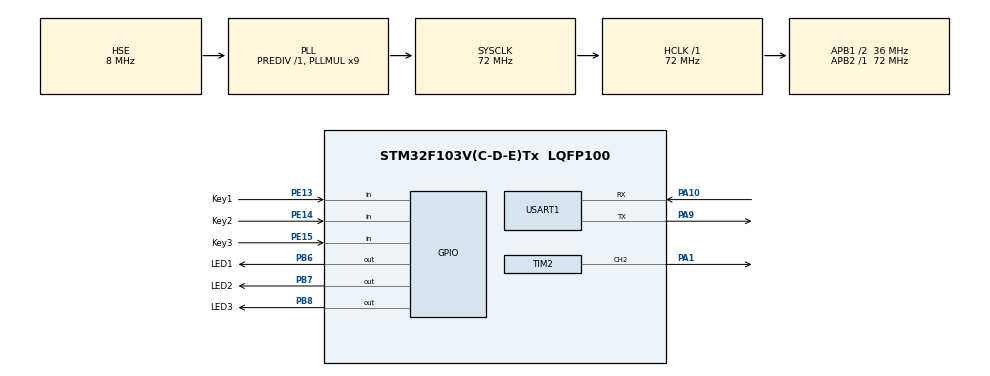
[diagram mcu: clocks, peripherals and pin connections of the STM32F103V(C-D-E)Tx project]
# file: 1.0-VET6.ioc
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Mcu.Family=STM32F1
Mcu.Name=STM32F103V(C-D-E)Tx
Mcu.Package=LQFP100
NVIC.PriorityGroup=NVIC_PRIORITYGROUP_4
NVIC.TIM2_IRQn=true\:2\:0\:true\:false\:true\:true\:true\:true
NVIC.TIM7_IRQn=true\:15\:0\:false\:false\:true\:false\:true\:true
NVIC.TimeBase=TIM7_IRQn
NVIC.TimeBaseIP=TIM7
OSC_IN.Mode=HSE-External-Oscillator
OSC_IN.Signal=RCC_OSC_IN
OSC_OUT.Mode=HSE-External-Oscillator
OSC_OUT.Signal=RCC_OSC_OUT
PA1.Signal=S_TIM2_CH2
PA10.Mode=Asynchronous
PA10.Signal=USART1_RX
PA13.Mode=Serial_Wire
PA13.Signal=SYS_JTMS-SWDIO
PA14.Mode=Serial_Wire
PA14.Signal=SYS_JTCK-SWCLK
PA9.Mode=Asynchronous
PA9.Signal=USART1_TX
PB6.GPIO_Label=LED1
PB6.GPIO_Speed=GPIO_SPEED_FREQ_HIGH
PB6.Signal=GPIO_Output
PB7.GPIO_Label=LED2
PB7.GPIO_Speed=GPIO_SPEED_FREQ_HIGH
PB7.Signal=GPIO_Output
PB8.GPIO_Label=LED3
PB8.GPIO_Speed=GPIO_SPEED_FREQ_HIGH
PB8.Signal=GPIO_Output
PC14-OSC32_IN.Mode=LSE-External-Oscillator
PC14-OSC32_IN.Signal=RCC_OSC32_IN
PC15-OSC32_OUT.Mode=LSE-External-Oscillator
PC15-OSC32_OUT.Signal=RCC_OSC32_OUT
PE13.GPIO_Label=Key1
PE13.Signal=GPIO_Input
PE14.GPIO_Label=Key2
PE14.Signal=GPIO_Input
PE15.GPIO_Label=Key3
PE15.Signal=GPIO_Input
ProjectManager.HeapSize=0x200
ProjectManager.StackSize=0x400
ProjectManager.TargetToolchain=MDK-ARM V5.32
RCC.AHBFreq_Value=72000000
RCC.APB1CLKDivider=RCC_HCLK_DIV2
RCC.APB1Freq_Value=36000000
RCC.APB1TimFreq_Value=72000000
RCC.APB2Freq_Value=72000000
RCC.APB2TimFreq_Value=72000000
RCC.HCLKFreq_Value=72000000
RCC.PLLMUL=RCC_PLL_MUL9
RCC.PLLSourceVirtual=RCC_PLLSOURCE_HSE
RCC.SYSCLKFreq_VALUE=72000000
RCC.SYSCLKSource=RCC_SYSCLKSOURCE_PLLCLK
RCC.USBFreq_Value=72000000
SH.S_TIM2_CH2.0=TIM2_CH2,PWM Generation2 CH2
TIM2.Channel-Output\ Compare1\ No\ Output=TIM_CHANNEL_1
TIM2.Channel-PWM\ Generation2\ CH2=TIM_CHANNEL_2
TIM2.Period=1000-1
TIM2.Prescaler=72-1
TIM2.Pulse-Output\ Compare1\ No\ Output=550
TIM2.Pulse-PWM\ Generation2\ CH2=500
USART1.VirtualMode=VM_ASYNC
VP_SYS_VS_tim7.Mode=TIM7
VP_TIM2_VS_ClockSourceINT.Mode=Internal
VP_TIM2_VS_no_output1.Mode=Output Compare1 No Output
board=custom

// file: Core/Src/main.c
/* USER CODE BEGIN Header */
/**
  ******************************************************************************
  * @file           : main.c
  * @brief          : Main program body
  ******************************************************************************
  * @attention
  *
  * Copyright (c) 2026 STMicroelectronics.
  * All rights reserved.
  *
  * This software is licensed under terms that can be found in the LICENSE file
  * in the root directory of this software component.
  * If no LICENSE file comes with this software, it is provided AS-IS.
  *
  ******************************************************************************
  */
/* USER CODE END Header */
#include "main.h"
#include "tim.h"
#include "usart.h"
#include "gpio.h"

void SystemClock_Config(void);

int main(void)
{

  /* USER CODE BEGIN 1 */
	uint16_t i=0;
  /* USER CODE END 1 */

  /* MCU Configuration--------------------------------------------------------*/

  /* Reset of all peripherals, Initializes the Flash interface and the Systick. */
  HAL_Init();

  /* Configure the system clock */
  SystemClock_Config();

  /* Initialize all configured peripherals */
  MX_GPIO_Init();
  MX_USART1_UART_Init();
  MX_TIM2_Init();
  /* USER CODE BEGIN 2 */
	HAL_TIM_OC_Start_IT(&htim2, TIM_CHANNEL_1);
	HAL_TIM_PWM_Start(&htim2, TIM_CHANNEL_2);

  /* USER CODE END 2 */

  /* Infinite loop */
  while (1)
  {

  }
}

void SystemClock_Config(void)
{
  RCC_OscInitTypeDef RCC_OscInitStruct = {0};
  RCC_ClkInitTypeDef RCC_ClkInitStruct = {0};

  /** Initializes the RCC Oscillators according to the specified parameters
  * in the RCC_OscInitTypeDef structure.
  */
  RCC_OscInitStruct.OscillatorType = RCC_OSCILLATORTYPE_HSE;
  RCC_OscInitStruct.HSEState = RCC_HSE_ON;
  RCC_OscInitStruct.HSEPredivValue = RCC_HSE_PREDIV_DIV1;
  RCC_OscInitStruct.HSIState = RCC_HSI_ON;
  RCC_OscInitStruct.PLL.PLLState = RCC_PLL_ON;
  RCC_OscInitStruct.PLL.PLLSource = RCC_PLLSOURCE_HSE;
  RCC_OscInitStruct.PLL.PLLMUL = RCC_PLL_MUL9;
  if (HAL_RCC_OscConfig(&RCC_OscInitStruct) != HAL_OK)
  {
    Error_Handler();
  }

  /** Initializes the CPU, AHB and APB buses clocks
  */
  RCC_ClkInitStruct.ClockType = RCC_CLOCKTYPE_HCLK|RCC_CLOCKTYPE_SYSCLK
                              |RCC_CLOCKTYPE_PCLK1|RCC_CLOCKTYPE_PCLK2;
  RCC_ClkInitStruct.SYSCLKSource = RCC_SYSCLKSOURCE_PLLCLK;
  RCC_ClkInitStruct.AHBCLKDivider = RCC_SYSCLK_DIV1;
  RCC_ClkInitStruct.APB1CLKDivider = RCC_HCLK_DIV2;
  RCC_ClkInitStruct.APB2CLKDivider = RCC_HCLK_DIV1;

  if (HAL_RCC_ClockConfig(&RCC_ClkInitStruct, FLASH_LATENCY_2) != HAL_OK)
  {
    Error_Handler();
  }
}

/* USER CODE BEGIN 4 */
void HAL_TIM_OC_DelayElapsedCallback(TIM_HandleTypeDef *htim)
{
    if(htim->Instance == TIM2)
    {
        if(htim->Channel == HAL_TIM_ACTIVE_CHANNEL_1)
        {
           HAL_GPIO_TogglePin(LED1_GPIO_Port,LED1_Pin);
        }
    }
}
/* USER CODE END 4 */

void HAL_TIM_PeriodElapsedCallback(TIM_HandleTypeDef *htim)
{
  if (htim->Instance == TIM7)
  {
    HAL_IncTick();
  }
}

void Error_Handler(void)
{
  __disable_irq();
  while (1)
  {
  }
}
